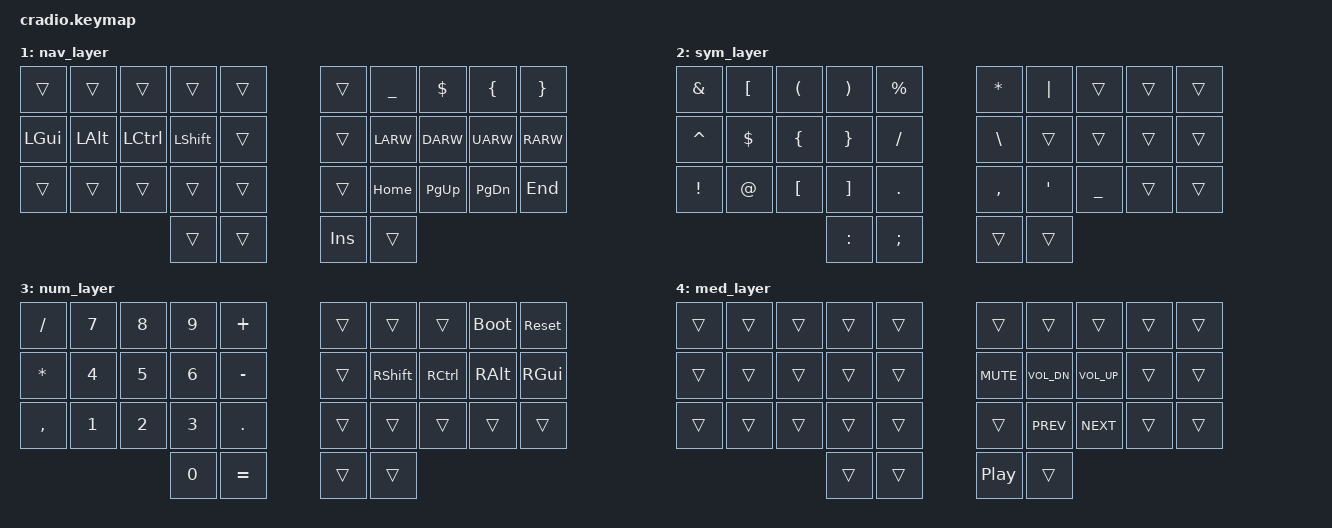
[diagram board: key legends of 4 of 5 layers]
// Copyright (c) 2022 The ZMK Contributors
// SPDX-License-Identifier: MIT

#include <behaviors.dtsi>
#include <dt-bindings/zmk/keys.h>
#include <dt-bindings/zmk/bt.h>

// Home row mods macro
//#define HRML(k1,k2,k3,k4) &ht LSHFT k1  &ht LALT k2  &ht LCTRL k3  &ht LGUI k4
#define HRML(k1,k2,k3,k4) &ht LGUI k1  &ht LALT k2  &ht LCTRL k3  &ht LSHFT k4
#define HRMR(k1,k2,k3,k4) &ht RSHFT k1  &ht RCTRL k2  &ht RALT k3  &ht RGUI k4
//#define HRMR(k1,k2,k3,k4) &ht RGUI k1  &ht RCTRL k2  &ht RALT k3  &ht RSHFT k4

#define DEF 0
#define NAV 1
#define SYM 2
#define NUM 3
#define MED 4

/ {
    behaviors {
        ht: hold_tap {
            compatible = "zmk,behavior-hold-tap";
            #binding-cells = <2>;
            flavor = "tap-preferred";
            tapping-term-ms = <220>;
            quick-tap-ms = <150>;
            require-prior-idle-ms = <100>;
            bindings = <&kp>, <&kp>;
        };
    };

    combos {
        compatible = "zmk,combos";
        combo_esc {
            timeout-ms = <520>;
            key-positions = <2 3>;
            bindings = <&kp ESC>;
        };
        combo_bsp {
            timeout-ms = <520>;
            key-positions = <6 7>;
            bindings = <&kp BSPC>;
        };
        combo_del {
            timeout-ms = <520>;
            key-positions = <26 27>;
            bindings = <&kp DELETE>;
        };
        combo_UNDER{
            timeout-ms = <520>;
            key-positions = <22 23>;
            bindings = <&kp UNDER>;
        };
    };

//    conditional_layers {
//        compatible = "zmk,conditional-layers";
//        tri_layer {
//            if-layers = <1 2 3>;
//            then-layer = <3>;
//        };
//    };

    keymap {
        compatible = "zmk,keymap";
        default_layer {
            bindings = <
        //╭──────────┬──────────┬──────────┬──────────┬──────────╮   ╭──────────┬──────────┬──────────┬──────────┬──────────╮
        //│  Q       │  W       │  E       │  R       │  T       │   │  Y       │  U       │  I       │  O       │  P       │
            &kp Q      &kp W      &kp E      &kp R      &kp T          &kp Y      &kp U      &kp I      &kp O      &kp P
        //├──────────┼──────────┼──────────┼──────────┼──────────┤   ├──────────┼──────────┼──────────┼──────────┼──────────┤
        //│  A       │  S       │  D       │  F       │  G       │   │  H       │  J       │  K       │  L       │ ; :      │
            HRML(A,        S,         D,         F)     &kp G          &kp H      HRMR(J,        K,         L,        SEMI)
        //├──────────┼──────────┼──────────┼──────────┼──────────┤   ├──────────┼──────────┼──────────┼──────────┼──────────┤
        //│  Z       │  X       │  C       │  V       │  B       │   │  N       │  M       │ , <      │ . >      │ / ?      │
            &kp Z      &kp X      &kp C      &kp V      &kp B          &kp N      &kp M      &kp COMMA  &kp DOT    &kp FSLH
        //╰──────────┴──────────┴──────────┼──────────┼──────────┤   ├──────────┼──────────┼──────────┴──────────┴──────────╯
                                        &lt NAV SPACE &lt MED TAB    &lt SYM ENTER &lt NUM BSPC
        //                                 ╰──────────┴──────────╯   ╰──────────┴──────────╯
            >;
        };

        // NAV

        nav_layer {
            bindings = <
        //╭──────────┬──────────┬──────────┬──────────┬──────────╮   ╭──────────┬──────────┬──────────┬──────────┬──────────╮
        //│          │          │          │          │          │   │          │ _        │ $        │ {        │  }       │
            &trans     &trans      &trans    &trans     &trans         &trans     &kp UNDER  &kp DLLR  &kp LBRC    &kp RBRC
        //├──────────┼──────────┼──────────┼──────────┼──────────┤   ├──────────┼──────────┼──────────┼──────────┼──────────┤
        //│          │          │          │          │          │   │          │ LEFT     │ DOWN     │ UP       │ RIGHT    │
            &kp LGUI   &kp LALT   &kp LCTRL  &kp LSHIFT &trans         &trans     &kp LARW   &kp DARW   &kp UARW   &kp RARW
        //├──────────┼──────────┼──────────┼──────────┼──────────┤   ├──────────┼──────────┼──────────┼──────────┼──────────┤
        //│          │          │          │          │          │   │          │ HOME     │ PAGE UP  │ PAGE DN  │ END      │
           &trans      &trans      &trans    &trans      &trans        &trans     &kp HOME   &kp PG_UP  &kp PG_DN &kp END
        //╰──────────┴──────────┴──────────┼──────────┼──────────┤   ├──────────┼──────────┼──────────┴──────────┴──────────╯
                                             &trans     &trans        &kp INS     &trans
        //                                 ╰──────────┴──────────╯   ╰──────────┴──────────╯
            >;
        };

        // SYM

        sym_layer {
            bindings = <
        //╭──────────┬──────────┬──────────┬──────────┬──────────╮   ╭──────────┬──────────┬──────────┬──────────┬──────────╮
        //│ &        │ #        │  (       │  )       │ %        │   │  *       │ |        │          │          │          │
            &kp AMPS   &kp LBKT   &kp LPAR   &kp RPAR   &kp PRCNT      &kp STAR  &kp PIPE   &trans     &trans     &trans
        //├──────────┼──────────┼──────────┼──────────┼──────────┤   ├──────────┼──────────┼──────────┼──────────┼──────────┤
        //│ ^        │  $       │  {       │  }       │  /       │   │  \       │          │          │          │          │
            &kp CARET   &kp DLLR   &kp LBRC   &kp RBRC   &kp FSLH      &kp BSLH  &trans      &trans     &trans     &trans
        //├──────────┼──────────┼──────────┼──────────┼──────────┤   ├──────────┼──────────┼──────────┼──────────┼──────────┤
        //│ !        │ @        │  [       │ ]        │ .        │   │ ,        │  '       │ _        │          │          │
            &kp EXCL   &kp AT     &kp LBKT   &kp RBKT   &kp DOT        &kp COMMA  &kp APOS   &kp UNDER   &trans   &trans
        //╰──────────┴──────────┴──────────┼──────────┼──────────┤   ├──────────┼──────────┼──────────┴──────────┴──────────╯
                                             &kp COLON  &kp SEMI         &trans     &trans
        //                                 ╰──────────┴──────────╯   ╰──────────┴──────────╯
            >;
        };

        // NUM

        num_layer {
            bindings = <
        //╭──────────┬──────────┬──────────┬──────────┬──────────╮   ╭──────────┬──────────┬──────────┬──────────┬──────────╮
        //│ /        │ 7        │ 8        │ 9        │ +        │   │          │          │          │ BOOTLOAD │  RESET   │
           &kp FSLH    &kp N7     &kp N8     &kp N9    &kp PLUS        &trans     &trans     &trans     &bootloader &sys_reset
        //├──────────┼──────────┼──────────┼──────────┼──────────┤   ├──────────┼──────────┼──────────┼──────────┼──────────┤
        //│ *        │ 4        │ 5        │ 6        │ -        │   │          │          │          │          │          │
            &kp STAR   &kp N4     &kp N5     &kp N6    &kp MINUS       &trans     &kp RSHIFT &kp RCTL   &kp RALT   &kp RGUI
        //├──────────┼──────────┼──────────┼──────────┼──────────┤   ├──────────┼──────────┼──────────┼──────────┼──────────┤
        //│ ,        │ 1        │ 2        │ 3        │.         │   │          │          │          │          │          │
            &kp COMMA  &kp N1     &kp N2      &kp N3    &kp DOT         &trans     &trans     &trans     &trans     &trans
        //╰──────────┴──────────┴──────────┼──────────┼──────────┤   ├──────────┼──────────┼──────────┴──────────┴──────────╯
                                             &kp N0     &kp EQUAL       &trans     &trans
        //                                 ╰──────────┴──────────╯   ╰──────────┴──────────╯
            >;
        };

        // MED

        med_layer {
            bindings = <
        //╭──────────┬──────────┬──────────┬──────────┬──────────╮   ╭──────────┬──────────┬──────────┬──────────┬──────────╮
        //│          │          │          │          │          │   │          │          │          │          │          │
           &trans      &trans     &trans     &trans     &trans         &trans     &trans     &trans     &trans     &trans
        //├──────────┼──────────┼──────────┼──────────┼──────────┤   ├──────────┼──────────┼──────────┼──────────┼──────────┤
        //│          │          │          │          │          │   │          │          │          │          │          │
            &trans     &trans     &trans     &trans     &trans         &kp C_MUTE &kp C_VOL_DN  &kp C_VOL_UP &trans  &trans
        //├──────────┼──────────┼──────────┼──────────┼──────────┤   ├──────────┼──────────┼──────────┼──────────┼──────────┤
        //│          │          │          │          │          │   │          │          │          │          │          │
            &trans     &trans     &trans     &trans     &trans         &trans     &kp C_PREV &kp C_NEXT &trans     &trans
        //╰──────────┴──────────┴──────────┼──────────┼──────────┤   ├──────────┼──────────┼──────────┴──────────┴──────────╯
                                             &trans     &trans         &kp C_PP   &trans
        //                                 ╰──────────┴──────────╯   ╰──────────┴──────────╯
            >;
        };

    };
};
